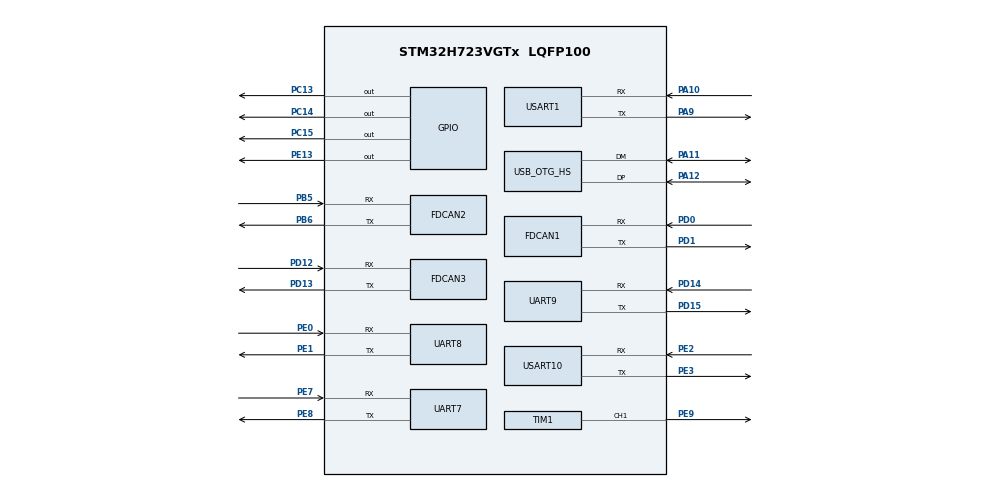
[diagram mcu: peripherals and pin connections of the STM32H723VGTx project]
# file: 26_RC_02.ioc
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CORTEX_M7.default_mode_Activation=1
Dma.Request0=UART7_RX
Dma.UART7_RX.0.Direction=DMA_PERIPH_TO_MEMORY
Dma.UART7_RX.0.EventEnable=DISABLE
Dma.UART7_RX.0.FIFOMode=DMA_FIFOMODE_DISABLE
Dma.UART7_RX.0.Instance=DMA1_Stream0
Dma.UART7_RX.0.MemDataAlignment=DMA_MDATAALIGN_BYTE
Dma.UART7_RX.0.MemInc=DMA_MINC_ENABLE
Dma.UART7_RX.0.Mode=DMA_CIRCULAR
Dma.UART7_RX.0.PeriphDataAlignment=DMA_PDATAALIGN_BYTE
Dma.UART7_RX.0.PeriphInc=DMA_PINC_DISABLE
Dma.UART7_RX.0.Polarity=HAL_DMAMUX_REQ_GEN_RISING
Dma.UART7_RX.0.Priority=DMA_PRIORITY_HIGH
Dma.UART7_RX.0.RequestNumber=1
Dma.UART7_RX.0.SignalID=NONE
Dma.UART7_RX.0.SyncEnable=DISABLE
Dma.UART7_RX.0.SyncPolarity=HAL_DMAMUX_SYNC_NO_EVENT
Dma.UART7_RX.0.SyncRequestNumber=1
Dma.UART7_RX.0.SyncSignalID=NONE
FDCAN1.AutoRetransmission=ENABLE
FDCAN1.CalculateBaudRateNominal=1000000
FDCAN1.CalculateTimeBitNominal=1000
FDCAN1.CalculateTimeQuantumNominal=12.5
FDCAN1.DataSyncJumpWidth=2
FDCAN1.DataTimeSeg1=13
FDCAN1.DataTimeSeg2=2
FDCAN1.ExtFiltersNbr=4
FDCAN1.NominalPrescaler=1
FDCAN1.NominalSyncJumpWidth=20
FDCAN1.NominalTimeSeg1=59
FDCAN1.NominalTimeSeg2=20
FDCAN1.RxBuffersNbr=2
FDCAN1.RxFifo0ElmtsNbr=10
FDCAN1.RxFifo1ElmtsNbr=10
FDCAN1.StdFiltersNbr=4
FDCAN1.TxBuffersNbr=10
FDCAN1.TxEventsNbr=10
FDCAN1.TxFifoQueueElmtsNbr=10
FDCAN2.AutoRetransmission=ENABLE
FDCAN2.CalculateBaudRateNominal=1000000
FDCAN2.CalculateTimeBitNominal=1000
FDCAN2.CalculateTimeQuantumNominal=12.5
FDCAN2.DataSyncJumpWidth=2
FDCAN2.DataTimeSeg1=13
FDCAN2.DataTimeSeg2=2
FDCAN2.ExtFiltersNbr=4
FDCAN2.MessageRAMOffset=850
FDCAN2.NominalPrescaler=1
FDCAN2.NominalSyncJumpWidth=20
FDCAN2.NominalTimeSeg1=59
FDCAN2.NominalTimeSeg2=20
FDCAN2.RxBuffersNbr=2
FDCAN2.RxFifo0ElmtsNbr=10
FDCAN2.RxFifo1ElmtsNbr=10
FDCAN2.StdFiltersNbr=4
FDCAN2.TxBuffersNbr=10
FDCAN2.TxEventsNbr=10
FDCAN2.TxFifoQueueElmtsNbr=10
FDCAN3.AutoRetransmission=ENABLE
FDCAN3.CalculateBaudRateNominal=1000000
FDCAN3.CalculateTimeBitNominal=1000
FDCAN3.CalculateTimeQuantumNominal=12.5
FDCAN3.DataSyncJumpWidth=2
FDCAN3.DataTimeSeg1=13
FDCAN3.DataTimeSeg2=2
FDCAN3.ExtFiltersNbr=4
FDCAN3.MessageRAMOffset=1700
FDCAN3.NominalPrescaler=1
FDCAN3.NominalSyncJumpWidth=20
FDCAN3.NominalTimeSeg1=59
FDCAN3.NominalTimeSeg2=20
FDCAN3.RxBuffersNbr=2
FDCAN3.RxFifo0ElmtsNbr=10
FDCAN3.RxFifo1ElmtsNbr=10
FDCAN3.StdFiltersNbr=4
FDCAN3.TxBuffersNbr=10
FDCAN3.TxEventsNbr=10
FDCAN3.TxFifoQueueElmtsNbr=10
FREERTOS.Tasks01=Start_Control_T,3,2048,Control_Task,As weak,NULL,Static,Start_Control_TBuffer,Start_Control_TControlBlock;Start_CAN_Task,2,2048,CAN_Task,As weak,NULL,Static,start_CAN_TaskBuffer,start_CAN_TaskControlBlock;Start_PCTX_Task,0,2048,PC_TX_Task,As weak,NULL,Static,Start_PCTX_TaskBuffer,Start_PCTX_TaskControlBlock;Start_PCRX_Task,1,2048,PC_RX_Task,As weak,NULL,Static,Start_PCRX_TaskBuffer,Start_PCRX_TaskControlBlock;Start_INS_Task,2,2048,INS_Task,As weak,NULL,Static,Start_INS_TaskBuffer,Start_INS_TaskControlBlock
Mcu.Family=STM32H7
Mcu.Name=STM32H723VGTx
Mcu.Package=LQFP100
NVIC.DMA1_Stream0_IRQn=true\:5\:0\:false\:false\:true\:true\:false\:true\:true
NVIC.FDCAN1_IT0_IRQn=true\:5\:0\:false\:false\:true\:true\:true\:true\:true
NVIC.FDCAN1_IT1_IRQn=true\:5\:0\:false\:false\:true\:true\:true\:true\:true
NVIC.FDCAN2_IT0_IRQn=true\:5\:0\:false\:false\:true\:true\:true\:true\:true
NVIC.FDCAN2_IT1_IRQn=true\:5\:0\:false\:false\:true\:true\:true\:true\:true
NVIC.FDCAN3_IT0_IRQn=true\:5\:0\:false\:false\:true\:true\:true\:true\:true
NVIC.FDCAN3_IT1_IRQn=true\:5\:0\:false\:false\:true\:true\:true\:true\:true
NVIC.OTG_HS_IRQn=true\:5\:0\:false\:false\:true\:true\:false\:true\:true
NVIC.PriorityGroup=NVIC_PRIORITYGROUP_4
NVIC.TIM2_IRQn=true\:15\:0\:false\:false\:true\:false\:false\:true\:true
NVIC.TIM3_IRQn=true\:5\:0\:false\:false\:true\:true\:true\:true\:true
NVIC.TimeBase=TIM2_IRQn
NVIC.TimeBaseIP=TIM2
NVIC.UART7_IRQn=true\:5\:0\:false\:false\:true\:true\:true\:true\:true
NVIC.UART8_IRQn=true\:5\:0\:false\:false\:true\:true\:true\:true\:true
NVIC.UART9_IRQn=true\:5\:0\:false\:false\:true\:true\:true\:true\:true
NVIC.USART10_IRQn=true\:5\:0\:false\:false\:true\:true\:true\:true\:true
NVIC.USART1_IRQn=true\:5\:0\:false\:false\:true\:true\:true\:true\:true
PA10.Mode=Asynchronous
PA10.Signal=USART1_RX
PA11.Mode=Device_Only_FS
PA11.Signal=USB_OTG_HS_DM
PA12.Mode=Device_Only_FS
PA12.Signal=USB_OTG_HS_DP
PA13(JTMS/SWDIO).Mode=Serial_Wire
PA13(JTMS/SWDIO).Signal=DEBUG_JTMS-SWDIO
PA14(JTCK/SWCLK).Mode=Serial_Wire
PA14(JTCK/SWCLK).Signal=DEBUG_JTCK-SWCLK
PA9.Mode=Asynchronous
PA9.Signal=USART1_TX
PB5.Mode=FDCAN_Activate
PB5.Signal=FDCAN2_RX
PB6.Mode=FDCAN_Activate
PB6.Signal=FDCAN2_TX
PC13.Signal=GPIO_Output
PC14-OSC32_IN.Signal=GPIO_Output
PC15-OSC32_OUT.Signal=GPIO_Output
PD0.Mode=FDCAN_Activate
PD0.Signal=FDCAN1_RX
PD1.Mode=FDCAN_Activate
PD1.Signal=FDCAN1_TX
PD12.Mode=FDCAN_Activate
PD12.Signal=FDCAN3_RX
PD13.Mode=FDCAN_Activate
PD13.Signal=FDCAN3_TX
PD14.Mode=Asynchronous
PD14.Signal=UART9_RX
PD15.Mode=Asynchronous
PD15.Signal=UART9_TX
PE0.Mode=Asynchronous
PE0.Signal=UART8_RX
PE1.Mode=Asynchronous
PE1.Signal=UART8_TX
PE13.Signal=GPIO_Output
PE2.Mode=Asynchronous
PE2.Signal=USART10_RX
PE3.Mode=Asynchronous
PE3.Signal=USART10_TX
PE7.Mode=Asynchronous
PE7.Signal=UART7_RX
PE8.Mode=Asynchronous
PE8.Signal=UART7_TX
PE9.Signal=S_TIM1_CH1
PH0-OSC_IN.Mode=HSE-External-Oscillator
PH0-OSC_IN.Signal=RCC_OSC_IN
PH1-OSC_OUT.Mode=HSE-External-Oscillator
PH1-OSC_OUT.Signal=RCC_OSC_OUT
ProjectManager.HeapSize=0x200
ProjectManager.StackSize=0x400
ProjectManager.TargetToolchain=MDK-ARM V5.32
RCC.ADCFreq_Value=48375000
RCC.APB1Freq_Value=120000000
RCC.APB2Freq_Value=120000000
RCC.APB3Freq_Value=120000000
RCC.APB4Freq_Value=120000000
RCC.CortexFreq_Value=480000000
RCC.D1PPRE=RCC_APB3_DIV2
RCC.D2PPRE1=RCC_APB1_DIV2
RCC.D2PPRE2=RCC_APB2_DIV2
RCC.D3PPRE=RCC_APB4_DIV2
RCC.DIVM1=2
RCC.DIVM3=16
RCC.DIVN1=40
RCC.DIVN3=256
RCC.DIVP1=1
RCC.DIVQ1=6
RCC.DIVQ3=8
RCC.HCLKFreq_Value=240000000
RCC.HPRE=RCC_HCLK_DIV2
RCC.HSE_VALUE=24000000
RCC.PLLFRACN=0
RCC.PLLSourceVirtual=RCC_PLLSOURCE_HSE
RCC.SYSCLKFreq_VALUE=480000000
RCC.SYSCLKSource=RCC_SYSCLKSOURCE_PLLCLK
RCC.USBCLockSelection=RCC_USBCLKSOURCE_PLL3
RCC.USBFreq_Value=48000000
SH.S_TIM1_CH1.0=TIM1_CH1,PWM Generation1 CH1
STMicroelectronics.X-CUBE-ALGOBUILD.1.5.0.LibraryCcDSPOoLibraryJjDSPOoLibrary=true
TIM1.AutomaticOutput=TIM_AUTOMATICOUTPUT_ENABLE
TIM1.Channel-PWM\ Generation1\ CH1=TIM_CHANNEL_1
TIM1.Period=20000-1
TIM1.Prescaler=240-1
TIM3.Period=1000-1
TIM3.Prescaler=240-1
USART1.VirtualMode-Asynchronous=VM_ASYNC
USART10.VirtualMode=VM_ASYNC
USB_DEVICE.CLASS_NAME_HS=CDC
USB_DEVICE.VirtualMode=Cdc
USB_DEVICE.VirtualModeHS=Cdc_HS
USB_OTG_HS.VirtualMode-Device_Only_FS=Device_Only_FS
VP_FREERTOS_VS_CMSIS_V1.Mode=CMSIS_V1
VP_MEMORYMAP_VS_MEMORYMAP.Mode=CurAppReg
VP_STMicroelectronics.X-CUBE-ALGOBUILD_VS_DSPOoLibraryJjLibrary_1.5.0_1.5.0.Mode=DSPOoLibraryJjLibrary
VP_SYS_VS_tim2.Mode=TIM2
VP_TIM1_VS_ClockSourceINT.Mode=Internal
VP_TIM3_VS_ClockSourceINT.Mode=Internal
VP_USB_DEVICE_VS_USB_DEVICE_CDC_HS.Mode=CDC_HS
board=custom

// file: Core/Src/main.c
/* USER CODE BEGIN Header */
/**
  ******************************************************************************
  * @file           : main.c
  * @brief          : Main program body
  ******************************************************************************
  * @attention
  *
  * Copyright (c) 2026 STMicroelectronics.
  * All rights reserved.
  *
  * This software is licensed under terms that can be found in the LICENSE file
  * in the root directory of this software component.
  * If no LICENSE file comes with this software, it is provided AS-IS.
  *
  ******************************************************************************
  */
/* USER CODE END Header */
#include "main.h"
#include "cmsis_os.h"
#include "dma.h"
#include "fdcan.h"
#include "memorymap.h"
#include "tim.h"
#include "usart.h"
#include "usb_device.h"
#include "gpio.h"

/* USER CODE BEGIN Includes */
#include "include.h"
#include "bsp_tick.h"
#include "bsp_mcu.h"
#include "Control_Task.h"
/* USER CODE END Includes */

void SystemClock_Config(void);
static void MPU_Config(void);
void MX_FREERTOS_Init(void);

int main(void)
{

  /* MPU Configuration--------------------------------------------------------*/
  MPU_Config();

  /* MCU Configuration--------------------------------------------------------*/

  /* Reset of all peripherals, Initializes the Flash interface and the Systick. */
  HAL_Init();

  /* Configure the system clock */
  SystemClock_Config();

  /* Initialize all configured peripherals */
  MX_GPIO_Init();
  MX_DMA_Init();
  MX_FDCAN1_Init();
  MX_FDCAN2_Init();
  MX_FDCAN3_Init();
  MX_TIM1_Init();
  MX_TIM3_Init();
  MX_UART7_Init();
  MX_USART10_UART_Init();
  MX_USART1_UART_Init();
  MX_UART8_Init();
  MX_UART9_Init();
  /* USER CODE BEGIN 2 */
  H7_power();
  /* USER CODE END 2 */

  /* Call init function for freertos objects (in cmsis_os2.c) */
  MX_FREERTOS_Init();

  /* Start scheduler */
  osKernelStart();

  /* We should never get here as control is now taken by the scheduler */

  /* Infinite loop */
  while (1)
  {

  }
}

void SystemClock_Config(void)
{
  RCC_OscInitTypeDef RCC_OscInitStruct = {0};
  RCC_ClkInitTypeDef RCC_ClkInitStruct = {0};

  /** Supply configuration update enable
  */
  HAL_PWREx_ConfigSupply(PWR_LDO_SUPPLY);

  /** Configure the main internal regulator output voltage
  */
  __HAL_PWR_VOLTAGESCALING_CONFIG(PWR_REGULATOR_VOLTAGE_SCALE0);

  while(!__HAL_PWR_GET_FLAG(PWR_FLAG_VOSRDY)) {}

  /** Initializes the RCC Oscillators according to the specified parameters
  * in the RCC_OscInitTypeDef structure.
  */
  RCC_OscInitStruct.OscillatorType = RCC_OSCILLATORTYPE_HSE;
  RCC_OscInitStruct.HSEState = RCC_HSE_ON;
  RCC_OscInitStruct.PLL.PLLState = RCC_PLL_ON;
  RCC_OscInitStruct.PLL.PLLSource = RCC_PLLSOURCE_HSE;
  RCC_OscInitStruct.PLL.PLLM = 2;
  RCC_OscInitStruct.PLL.PLLN = 40;
  RCC_OscInitStruct.PLL.PLLP = 1;
  RCC_OscInitStruct.PLL.PLLQ = 6;
  RCC_OscInitStruct.PLL.PLLR = 2;
  RCC_OscInitStruct.PLL.PLLRGE = RCC_PLL1VCIRANGE_3;
  RCC_OscInitStruct.PLL.PLLVCOSEL = RCC_PLL1VCOWIDE;
  RCC_OscInitStruct.PLL.PLLFRACN = 0;
  if (HAL_RCC_OscConfig(&RCC_OscInitStruct) != HAL_OK)
  {
    Error_Handler();
  }

  /** Initializes the CPU, AHB and APB buses clocks
  */
  RCC_ClkInitStruct.ClockType = RCC_CLOCKTYPE_HCLK|RCC_CLOCKTYPE_SYSCLK
                              |RCC_CLOCKTYPE_PCLK1|RCC_CLOCKTYPE_PCLK2
                              |RCC_CLOCKTYPE_D3PCLK1|RCC_CLOCKTYPE_D1PCLK1;
  RCC_ClkInitStruct.SYSCLKSource = RCC_SYSCLKSOURCE_PLLCLK;
  RCC_ClkInitStruct.SYSCLKDivider = RCC_SYSCLK_DIV1;
  RCC_ClkInitStruct.AHBCLKDivider = RCC_HCLK_DIV2;
  RCC_ClkInitStruct.APB3CLKDivider = RCC_APB3_DIV2;
  RCC_ClkInitStruct.APB1CLKDivider = RCC_APB1_DIV2;
  RCC_ClkInitStruct.APB2CLKDivider = RCC_APB2_DIV2;
  RCC_ClkInitStruct.APB4CLKDivider = RCC_APB4_DIV2;

  if (HAL_RCC_ClockConfig(&RCC_ClkInitStruct, FLASH_LATENCY_3) != HAL_OK)
  {
    Error_Handler();
  }
}

 /* MPU Configuration */

void MPU_Config(void)
{
  MPU_Region_InitTypeDef MPU_InitStruct = {0};

  /* Disables the MPU */
  HAL_MPU_Disable();

  /** Initializes and configures the Region and the memory to be protected
  */
  MPU_InitStruct.Enable = MPU_REGION_ENABLE;
  MPU_InitStruct.Number = MPU_REGION_NUMBER0;
  MPU_InitStruct.BaseAddress = 0x0;
  MPU_InitStruct.Size = MPU_REGION_SIZE_4GB;
  MPU_InitStruct.SubRegionDisable = 0x87;
  MPU_InitStruct.TypeExtField = MPU_TEX_LEVEL0;
  MPU_InitStruct.AccessPermission = MPU_REGION_NO_ACCESS;
  MPU_InitStruct.DisableExec = MPU_INSTRUCTION_ACCESS_DISABLE;
  MPU_InitStruct.IsShareable = MPU_ACCESS_SHAREABLE;
  MPU_InitStruct.IsCacheable = MPU_ACCESS_NOT_CACHEABLE;
  MPU_InitStruct.IsBufferable = MPU_ACCESS_NOT_BUFFERABLE;

  HAL_MPU_ConfigRegion(&MPU_InitStruct);
  /* Enables the MPU */
  HAL_MPU_Enable(MPU_PRIVILEGED_DEFAULT);

}

void HAL_TIM_PeriodElapsedCallback(TIM_HandleTypeDef *htim)
{
  if (htim->Instance == TIM2)
  {
    HAL_IncTick();
  }
  /* USER CODE BEGIN Callback 1 */
    if (htim->Instance == TIM3)
  {
    control_tim1mscallback();
  }

  /* USER CODE END Callback 1 */
}

void Error_Handler(void)
{
  __disable_irq();
  while (1)
  {
  }
}

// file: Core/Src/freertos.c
/* USER CODE BEGIN Header */
/**
  ******************************************************************************
  * File Name          : freertos.c
  * Description        : Code for freertos applications
  ******************************************************************************
  * @attention
  *
  * Copyright (c) 2026 STMicroelectronics.
  * All rights reserved.
  *
  * This software is licensed under terms that can be found in the LICENSE file
  * in the root directory of this software component.
  * If no LICENSE file comes with this software, it is provided AS-IS.
  *
  ******************************************************************************
  */
/* USER CODE END Header */

#include "FreeRTOS.h"
#include "task.h"
#include "main.h"
#include "cmsis_os.h"

osThreadId Start_Control_THandle;
uint32_t Start_Control_TBuffer[ 2048 ];
osStaticThreadDef_t Start_Control_TControlBlock;
osThreadId Start_CAN_TaskHandle;
uint32_t start_CAN_TaskBuffer[ 2048 ];
osStaticThreadDef_t start_CAN_TaskControlBlock;
osThreadId Start_PCTX_TaskHandle;
uint32_t Start_PCTX_TaskBuffer[ 2048 ];
osStaticThreadDef_t Start_PCTX_TaskControlBlock;
osThreadId Start_PCRX_TaskHandle;
uint32_t Start_PCRX_TaskBuffer[ 2048 ];
osStaticThreadDef_t Start_PCRX_TaskControlBlock;
osThreadId Start_INS_TaskHandle;
uint32_t Start_INS_TaskBuffer[ 2048 ];
osStaticThreadDef_t Start_INS_TaskControlBlock;

void Control_Task(void const * argument);
void CAN_Task(void const * argument);
void PC_TX_Task(void const * argument);
void PC_RX_Task(void const * argument);
void INS_Task(void const * argument);

extern void MX_USB_DEVICE_Init(void);
void MX_FREERTOS_Init(void); /* (MISRA C 2004 rule 8.1) */

/* GetIdleTaskMemory prototype (linked to static allocation support) */
void vApplicationGetIdleTaskMemory( StaticTask_t **ppxIdleTaskTCBBuffer, StackType_t **ppxIdleTaskStackBuffer, uint32_t *pulIdleTaskStackSize );

/* USER CODE BEGIN GET_IDLE_TASK_MEMORY */
static StaticTask_t xIdleTaskTCBBuffer;
static StackType_t xIdleStack[configMINIMAL_STACK_SIZE];

void vApplicationGetIdleTaskMemory( StaticTask_t **ppxIdleTaskTCBBuffer, StackType_t **ppxIdleTaskStackBuffer, uint32_t *pulIdleTaskStackSize )
{
  *ppxIdleTaskTCBBuffer = &xIdleTaskTCBBuffer;
  *ppxIdleTaskStackBuffer = &xIdleStack[0];
  *pulIdleTaskStackSize = configMINIMAL_STACK_SIZE;
  /* place for user code */
}
/* USER CODE END GET_IDLE_TASK_MEMORY */

void MX_FREERTOS_Init(void) {

  /* Create the thread(s) */
  /* definition and creation of Start_Control_T */
  osThreadStaticDef(Start_Control_T, Control_Task, osPriorityRealtime, 0, 2048, Start_Control_TBuffer, &Start_Control_TControlBlock);
  Start_Control_THandle = osThreadCreate(osThread(Start_Control_T), NULL);

  /* definition and creation of Start_CAN_Task */
  osThreadStaticDef(Start_CAN_Task, CAN_Task, osPriorityHigh, 0, 2048, start_CAN_TaskBuffer, &start_CAN_TaskControlBlock);
  Start_CAN_TaskHandle = osThreadCreate(osThread(Start_CAN_Task), NULL);

  /* definition and creation of Start_PCTX_Task */
  osThreadStaticDef(Start_PCTX_Task, PC_TX_Task, osPriorityNormal, 0, 2048, Start_PCTX_TaskBuffer, &Start_PCTX_TaskControlBlock);
  Start_PCTX_TaskHandle = osThreadCreate(osThread(Start_PCTX_Task), NULL);

  /* definition and creation of Start_PCRX_Task */
  osThreadStaticDef(Start_PCRX_Task, PC_RX_Task, osPriorityAboveNormal, 0, 2048, Start_PCRX_TaskBuffer, &Start_PCRX_TaskControlBlock);
  Start_PCRX_TaskHandle = osThreadCreate(osThread(Start_PCRX_Task), NULL);

  /* definition and creation of Start_INS_Task */
  osThreadStaticDef(Start_INS_Task, INS_Task, osPriorityHigh, 0, 2048, Start_INS_TaskBuffer, &Start_INS_TaskControlBlock);
  Start_INS_TaskHandle = osThreadCreate(osThread(Start_INS_Task), NULL);

}

__weak void Control_Task(void const * argument)
{
  /* init code for USB_DEVICE */
  MX_USB_DEVICE_Init();
  for(;;)
  {
    osDelay(1);
  }
}

__weak void CAN_Task(void const * argument)
{
  for(;;)
  {
    osDelay(1);
  }
}

__weak void PC_TX_Task(void const * argument)
{
  for(;;)
  {
    osDelay(1);
  }
}

__weak void PC_RX_Task(void const * argument)
{
  for(;;)
  {
    osDelay(1);
  }
}

__weak void INS_Task(void const * argument)
{
  for(;;)
  {
    osDelay(1);
  }
}
